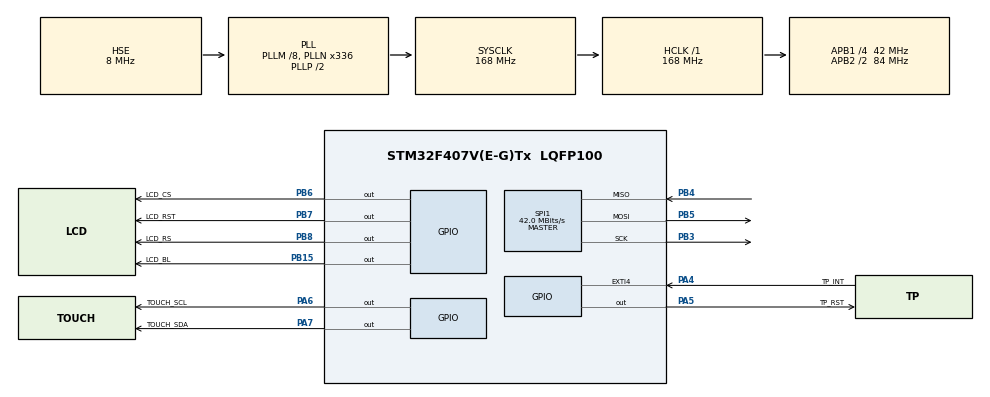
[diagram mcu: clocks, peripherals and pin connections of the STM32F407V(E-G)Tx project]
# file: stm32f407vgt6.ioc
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Dma.Request0=SPI1_TX
Dma.SPI1_TX.0.Direction=DMA_MEMORY_TO_PERIPH
Dma.SPI1_TX.0.FIFOMode=DMA_FIFOMODE_DISABLE
Dma.SPI1_TX.0.Instance=DMA2_Stream3
Dma.SPI1_TX.0.MemDataAlignment=DMA_MDATAALIGN_BYTE
Dma.SPI1_TX.0.MemInc=DMA_MINC_ENABLE
Dma.SPI1_TX.0.Mode=DMA_NORMAL
Dma.SPI1_TX.0.PeriphDataAlignment=DMA_PDATAALIGN_BYTE
Dma.SPI1_TX.0.PeriphInc=DMA_PINC_DISABLE
Dma.SPI1_TX.0.Priority=DMA_PRIORITY_LOW
IWDG.Prescaler=IWDG_PRESCALER_128
IWDG.Reload=2000
Mcu.Family=STM32F4
Mcu.Name=STM32F407V(E-G)Tx
Mcu.Package=LQFP100
NVIC.DMA2_Stream3_IRQn=true\:0\:0\:false\:false\:true\:false\:true\:true
NVIC.EXTI4_IRQn=true\:0\:0\:false\:false\:true\:true\:true\:true
NVIC.PriorityGroup=NVIC_PRIORITYGROUP_4
NVIC.TIM2_IRQn=true\:0\:0\:false\:false\:true\:true\:true\:true
PA13.Signal=SYS_JTMS-SWDIO
PA14.Signal=SYS_JTCK-SWCLK
PA4.GPIO_Label=TP_INT
PA4.Signal=GPXTI4
PA5.GPIO_Label=TP_RST
PA5.Signal=GPIO_Output
PA6.GPIO_Label=TOUCH_SCL
PA6.GPIO_ModeDefaultOutputPP=GPIO_MODE_OUTPUT_OD
PA6.GPIO_PuPd=GPIO_PULLUP
PA6.GPIO_Speed=GPIO_SPEED_FREQ_HIGH
PA6.Signal=GPIO_Output
PA7.GPIO_Label=TOUCH_SDA
PA7.GPIO_ModeDefaultOutputPP=GPIO_MODE_OUTPUT_OD
PA7.GPIO_PuPd=GPIO_PULLUP
PA7.GPIO_Speed=GPIO_SPEED_FREQ_HIGH
PA7.Signal=GPIO_Output
PB15.GPIO_Label=LCD_BL
PB15.Signal=GPIO_Output
PB3.Mode=Full_Duplex_Master
PB3.Signal=SPI1_SCK
PB4.Mode=Full_Duplex_Master
PB4.Signal=SPI1_MISO
PB5.Mode=Full_Duplex_Master
PB5.Signal=SPI1_MOSI
PB6.GPIO_Label=LCD_CS
PB6.GPIO_PuPd=GPIO_PULLUP
PB6.GPIO_Speed=GPIO_SPEED_FREQ_HIGH
PB6.Signal=GPIO_Output
PB7.GPIO_Label=LCD_RST
PB7.Signal=GPIO_Output
PB8.GPIO_Label=LCD_RS
PB8.Signal=GPIO_Output
PH0-OSC_IN.Mode=HSE-External-Oscillator
PH0-OSC_IN.Signal=RCC_OSC_IN
PH1-OSC_OUT.Mode=HSE-External-Oscillator
PH1-OSC_OUT.Signal=RCC_OSC_OUT
ProjectManager.HeapSize=0x200
ProjectManager.StackSize=0x400
ProjectManager.TargetToolchain=CMake
RCC.48MHZClocksFreq_Value=48000000
RCC.AHBFreq_Value=168000000
RCC.APB1CLKDivider=RCC_HCLK_DIV4
RCC.APB1Freq_Value=42000000
RCC.APB1TimFreq_Value=84000000
RCC.APB2CLKDivider=RCC_HCLK_DIV2
RCC.APB2Freq_Value=84000000
RCC.APB2TimFreq_Value=168000000
RCC.CortexFreq_Value=168000000
RCC.HCLKFreq_Value=168000000
RCC.HSE_VALUE=8000000
RCC.HSI_VALUE=16000000
RCC.LSE_VALUE=32768
RCC.PLLM=8
RCC.PLLN=336
RCC.PLLQ=7
RCC.PLLSourceVirtual=RCC_PLLSOURCE_HSE
RCC.RCC_RTC_Clock_Source=RCC_RTCCLKSOURCE_LSE
RCC.RCC_RTC_Clock_SourceVirtual=RCC_RTCCLKSOURCE_LSE
RCC.SYSCLKFreq_VALUE=168000000
RCC.SYSCLKSource=RCC_SYSCLKSOURCE_PLLCLK
RCC.VCOOutputFreq_Value=336000000
RCC.VDD_VALUE=3
SPI1.CalculateBaudRate=42.0 MBits/s
SPI1.Direction=SPI_DIRECTION_2LINES
SPI1.Mode=SPI_MODE_MASTER
SPI1.VirtualType=VM_MASTER
TIM2.AutoReloadPreload=TIM_AUTORELOAD_PRELOAD_ENABLE
TIM2.Period=666
TIM2.Prescaler=8400-1
VP_IWDG_VS_IWDG.Mode=IWDG_Activate
VP_TIM2_VS_ClockSourceINT.Mode=Internal
board=custom

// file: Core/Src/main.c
/* USER CODE BEGIN Header */
/**
  ******************************************************************************
  * @file           : main.c
  * @brief          : Main program body
  ******************************************************************************
  * @attention
  *
  * Copyright (c) 2026 STMicroelectronics.
  * All rights reserved.
  *
  * This software is licensed under terms that can be found in the LICENSE file
  * in the root directory of this software component.
  * If no LICENSE file comes with this software, it is provided AS-IS.
  *
  ******************************************************************************
  */
/* USER CODE END Header */
#include "main.h"
#include "dma.h"
#include "iwdg.h"
#include "spi.h"
#include "tim.h"
#include "gpio.h"

void SystemClock_Config(void);

int main(void)
{

  /* MCU Configuration--------------------------------------------------------*/

  /* Reset of all peripherals, Initializes the Flash interface and the Systick. */
  HAL_Init();

  /* Configure the system clock */
  SystemClock_Config();

  /* Initialize all configured peripherals */
  MX_GPIO_Init();
  MX_DMA_Init();
  MX_SPI1_Init();
  MX_TIM2_Init();
  // MX_IWDG_Init();
  /* USER CODE BEGIN 2 */
void init_all(void);
void loop_run(void);

  init_all();
  loop_run();
  /* USER CODE END 2 */

  /* Infinite loop */
  while (1)
  {

  }
}

void SystemClock_Config(void)
{
  RCC_OscInitTypeDef RCC_OscInitStruct = {0};
  RCC_ClkInitTypeDef RCC_ClkInitStruct = {0};

  /** Configure the main internal regulator output voltage
  */
  __HAL_RCC_PWR_CLK_ENABLE();
  __HAL_PWR_VOLTAGESCALING_CONFIG(PWR_REGULATOR_VOLTAGE_SCALE1);

  /** Initializes the RCC Oscillators according to the specified parameters
  * in the RCC_OscInitTypeDef structure.
  */
  RCC_OscInitStruct.OscillatorType = RCC_OSCILLATORTYPE_LSI|RCC_OSCILLATORTYPE_HSE;
  RCC_OscInitStruct.HSEState = RCC_HSE_ON;
  RCC_OscInitStruct.LSIState = RCC_LSI_ON;
  RCC_OscInitStruct.PLL.PLLState = RCC_PLL_ON;
  RCC_OscInitStruct.PLL.PLLSource = RCC_PLLSOURCE_HSE;
  RCC_OscInitStruct.PLL.PLLM = 8;
  RCC_OscInitStruct.PLL.PLLN = 336;
  RCC_OscInitStruct.PLL.PLLP = RCC_PLLP_DIV2;
  RCC_OscInitStruct.PLL.PLLQ = 7;
  if (HAL_RCC_OscConfig(&RCC_OscInitStruct) != HAL_OK)
  {
    Error_Handler();
  }

  /** Initializes the CPU, AHB and APB buses clocks
  */
  RCC_ClkInitStruct.ClockType = RCC_CLOCKTYPE_HCLK|RCC_CLOCKTYPE_SYSCLK
                              |RCC_CLOCKTYPE_PCLK1|RCC_CLOCKTYPE_PCLK2;
  RCC_ClkInitStruct.SYSCLKSource = RCC_SYSCLKSOURCE_PLLCLK;
  RCC_ClkInitStruct.AHBCLKDivider = RCC_SYSCLK_DIV1;
  RCC_ClkInitStruct.APB1CLKDivider = RCC_HCLK_DIV4;
  RCC_ClkInitStruct.APB2CLKDivider = RCC_HCLK_DIV2;

  if (HAL_RCC_ClockConfig(&RCC_ClkInitStruct, FLASH_LATENCY_5) != HAL_OK)
  {
    Error_Handler();
  }
}

/* USER CODE BEGIN 4 */
void HAL_GPIO_EXTI_Callback(uint16_t GPIO_Pin)
{
  // #define PULSE_NUM_CALCUTE 5
  // static uint32_t time_start;
  // static uint16_t pulse_num = 0;
  if (GPIO_Pin == TP_INT_Pin)
  {
  }
}
/* USER CODE END 4 */

void Error_Handler(void)
{
  __disable_irq();
  while (1)
  {
  }
}
